# CY8C5888LTI_LP097 register map
File version: 0.1
CY8C58LP
Registers are 8-bit, read-write, no defined reset value unless marked. A register's access mark holds for its fields unless they carry their own. Offsets are from the block's base; lines under a group give offsets from that group; [hi:lo] are bit positions; {n}, {i} and the like mark numbered series; 'fields as' and 'values as' point back to an identical list; <NAME> marks a mode.

## Memory map
0x00000000 screen2 — UART
0x00000000 PRINTER_A — UART
0x00000000 PRINTER_B — UART
0x00000000 screen — UART
0x00000000 PWM_1
0x00000000 GBCL — UART
0x00000000 MEPSAN — UART

## screen2 — UART
Base 0x00000000
0x4000642D RX_screen2_RX_ADDRESS1 — RX Address1 Register
0x4000643D RX_screen2_RX_ADDRESS2 — RX Address2 Register
0x40006444 TX_screen2_TX_DATA — TX Data Register
0x4000644D RX_screen2_RX_DATA — RX Data Register
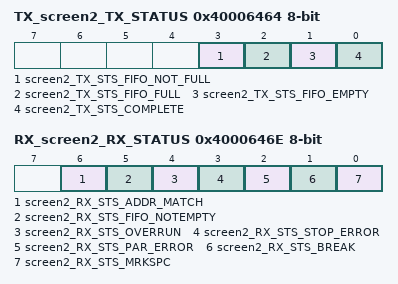
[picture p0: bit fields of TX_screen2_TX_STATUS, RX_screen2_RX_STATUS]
0x40006464 TX_screen2_TX_STATUS — TX status register
  [3] screen2_TX_STS_FIFO_NOT_FULL ro, [2] screen2_TX_STS_FIFO_FULL ro, [1] screen2_TX_STS_FIFO_EMPTY ro, [0] screen2_TX_STS_COMPLETE ro
0x4000646E RX_screen2_RX_STATUS — RX status register
  [6] screen2_RX_STS_ADDR_MATCH ro, [5] screen2_RX_STS_FIFO_NOTEMPTY ro, [4] screen2_RX_STS_OVERRUN ro, [3] screen2_RX_STS_STOP_ERROR ro, [2] screen2_RX_STS_PAR_ERROR ro, [1] screen2_RX_STS_BREAK ro, [0] screen2_RX_STS_MRKSPC ro

## PRINTER_A — UART
Base 0x00000000
0x40006446 TX_PRINTER_A_TX_DATA — TX Data Register
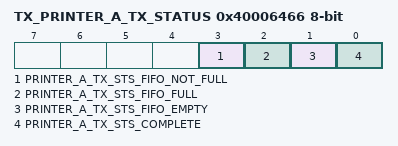
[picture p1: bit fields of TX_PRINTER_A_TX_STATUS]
0x40006466 TX_PRINTER_A_TX_STATUS — TX status register
  [3] PRINTER_A_TX_STS_FIFO_NOT_FULL ro, [2] PRINTER_A_TX_STS_FIFO_FULL ro, [1] PRINTER_A_TX_STS_FIFO_EMPTY ro, [0] PRINTER_A_TX_STS_COMPLETE ro

## PRINTER_B — UART
Base 0x00000000
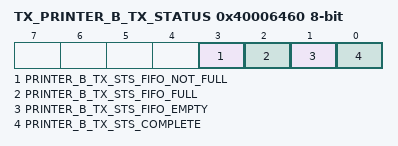
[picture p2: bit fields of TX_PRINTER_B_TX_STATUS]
0x40006460 TX_PRINTER_B_TX_STATUS — TX status register
  [3] PRINTER_B_TX_STS_FIFO_NOT_FULL ro, [2] PRINTER_B_TX_STS_FIFO_FULL ro, [1] PRINTER_B_TX_STS_FIFO_EMPTY ro, [0] PRINTER_B_TX_STS_COMPLETE ro
0x4000654B TX_PRINTER_B_TX_DATA — TX Data Register

## screen — UART
Base 0x00000000
0x4000644C TX_screen_TX_DATA — TX Data Register
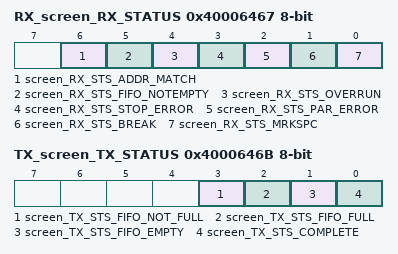
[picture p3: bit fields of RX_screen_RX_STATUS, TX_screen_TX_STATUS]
0x40006467 RX_screen_RX_STATUS — RX status register
  [6] screen_RX_STS_ADDR_MATCH ro, [5] screen_RX_STS_FIFO_NOTEMPTY ro, [4] screen_RX_STS_OVERRUN ro, [3] screen_RX_STS_STOP_ERROR ro, [2] screen_RX_STS_PAR_ERROR ro, [1] screen_RX_STS_BREAK ro, [0] screen_RX_STS_MRKSPC ro
0x4000646B TX_screen_TX_STATUS — TX status register
  [3] screen_TX_STS_FIFO_NOT_FULL ro, [2] screen_TX_STS_FIFO_FULL ro, [1] screen_TX_STS_FIFO_EMPTY ro, [0] screen_TX_STS_COMPLETE ro
0x40006527 RX_screen_RX_ADDRESS1 — RX Address1 Register
0x40006537 RX_screen_RX_ADDRESS2 — RX Address2 Register
0x40006547 RX_screen_RX_DATA — RX Data Register

## PWM_1
Base 0x00000000
0x400043A3 PWM_1_GLOBAL_ENABLE — PM.ACT.CFG
  [3:0] en_timer — Enable timer/counters.
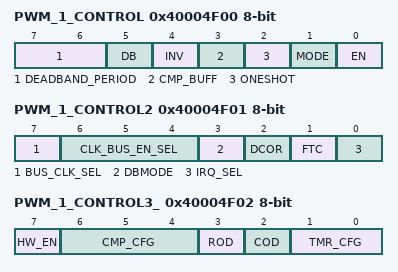
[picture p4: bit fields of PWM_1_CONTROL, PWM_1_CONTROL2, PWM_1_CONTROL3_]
0x40004F00 PWM_1_CONTROL — TMRx.CFG0
  [7:6] DEADBAND_PERIOD
  [5] DB — Deadband mode--Deadband phases phi1 and phi2 are outputted on CMP and TC output pins respectively.
    0=Timer (CMP and TC are output.); 1=Deadband (PHI1 (instead of CMP) and PHI2 (instead of TC) are output.)
  [4] INV — Invert sense of TIMEREN signal
  [3] CMP_BUFF — Buffer compare register. Compare register updates only on timer terminal count.
  [2] ONESHOT — Timer stops upon reaching stop condition defined by TMR_CFG bits. Can be restarted by asserting TIMER RESET or disabling and re-enabling block.
  [1] MODE — Mode. (0 = Timer; 1 = Comparator)
    0=Timer mode. CNT/CMP register holds timer count value.; 1=Comparator mode. CNT/CMP register holds comparator threshold value.
  [0] EN — Enables timer/comparator.
0x40004F01 PWM_1_CONTROL2 — TMRx.CFG1
  [7] BUS_CLK_SEL — Bus Clock selection.
  [6:4] CLK_BUS_EN_SEL — Digital Global Clock selection.
  [3] DBMODE — Deadband mode (asynchronous/synchronous). CMP output pin is also affected when not in deadband mode (CFG0.DEADBAND).
  [2] DCOR — Disable Clear on Read (DCOR) of Status Register SR0.
  [1] FTC — First Terminal Count (FTC). Setting this bit forces a single pulse on the TC pin when first enabled.
    0=Disable_FTC (Disable the single cycle pulse, which signifies the timer is starting.); 1=Enable_FTC (Enable the single cycle pulse, which signifies the timer is starting.)
  [0] IRQ_SEL — Irq selection. (0 = raw interrupts; 1 = status register interrupts)
0x40004F02 PWM_1_CONTROL3_ — TMRx.CFG2
  [7] HW_EN — When set Timer Enable controls counting.
  [6:4] CMP_CFG — Comparator configurations
    0=Equal (Compare Equal); 1=Less_than (Compare Less Than); 2=Less_than_or_equal (Compare Less Than or Equal .); 3=Greater (Compare Greater Than .); 4=Greater_than_or_equal (Compare Greater Than or Equal)
  [3] ROD — Reset On Disable (ROD). Resets internal state of output logic
  [2] COD — Clear On Disable (COD). Clears or gates outputs to zero.
  [1:0] TMR_CFG — Timer configuration (MODE = 0): 000 = Continuous; 001 = Pulsewidth; 010 = Period; 011 = Stop on IRQ
    0=Continuous (Timer runs while EN bit of CFG0 register is set to '1'.); 1=Pulsewidth (Timer runs from positive to negative edge of TIMEREN.); 2=Period (Timer runs from positive to positive edge of TIMEREN.); 3=Irq (Timer runs until IRQ.)
0x40004F04 PWM_1_PERIOD — TMRx.PER0 - Assigned Period
0x40004F06 PWM_1_COMPARE — TMRx.CNT_CMP0 - Assigned Compare Value

## GBCL — UART
Base 0x00000000
0x40006529 RX_GBCL_RX_ADDRESS1 — RX Address1 Register
0x40006539 RX_GBCL_RX_ADDRESS2 — RX Address2 Register
0x40006544 TX_GBCL_TX_DATA — TX Data Register
0x40006549 RX_GBCL_RX_DATA — RX Data Register
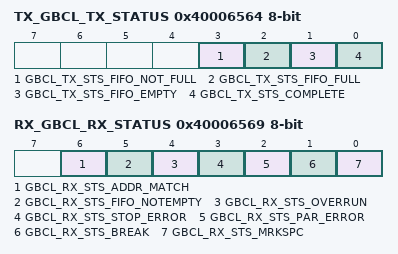
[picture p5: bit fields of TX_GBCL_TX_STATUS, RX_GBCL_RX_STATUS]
0x40006564 TX_GBCL_TX_STATUS — TX status register
  [3] GBCL_TX_STS_FIFO_NOT_FULL ro, [2] GBCL_TX_STS_FIFO_FULL ro, [1] GBCL_TX_STS_FIFO_EMPTY ro, [0] GBCL_TX_STS_COMPLETE ro
0x40006569 RX_GBCL_RX_STATUS — RX status register
  [6] GBCL_RX_STS_ADDR_MATCH ro, [5] GBCL_RX_STS_FIFO_NOTEMPTY ro, [4] GBCL_RX_STS_OVERRUN ro, [3] GBCL_RX_STS_STOP_ERROR ro, [2] GBCL_RX_STS_PAR_ERROR ro, [1] GBCL_RX_STS_BREAK ro, [0] GBCL_RX_STS_MRKSPC ro

## MEPSAN — UART
Base 0x00000000
0x40006429 RX_MEPSAN_RX_ADDRESS1 — RX Address1 Register
0x40006439 RX_MEPSAN_RX_ADDRESS2 — RX Address2 Register
0x40006441 TX_MEPSAN_TX_DATA — TX Data Register
0x40006449 RX_MEPSAN_RX_DATA — RX Data Register
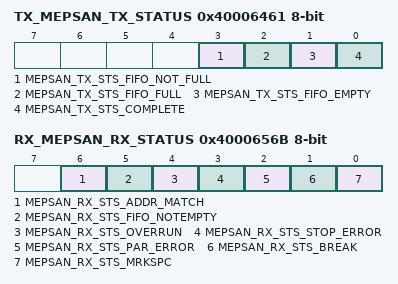
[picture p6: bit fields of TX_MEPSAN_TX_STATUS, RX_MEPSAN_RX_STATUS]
0x40006461 TX_MEPSAN_TX_STATUS — TX status register
  [3] MEPSAN_TX_STS_FIFO_NOT_FULL ro, [2] MEPSAN_TX_STS_FIFO_FULL ro, [1] MEPSAN_TX_STS_FIFO_EMPTY ro, [0] MEPSAN_TX_STS_COMPLETE ro
0x4000656B RX_MEPSAN_RX_STATUS — RX status register
  [6] MEPSAN_RX_STS_ADDR_MATCH ro, [5] MEPSAN_RX_STS_FIFO_NOTEMPTY ro, [4] MEPSAN_RX_STS_OVERRUN ro, [3] MEPSAN_RX_STS_STOP_ERROR ro, [2] MEPSAN_RX_STS_PAR_ERROR ro, [1] MEPSAN_RX_STS_BREAK ro, [0] MEPSAN_RX_STS_MRKSPC ro
